# tle984x register map
Vendor: Infineon; File version: 1.9.5
CPU: CM0 r2p1, little endian, no MPU, no FPU, 2 interrupt priority bits
Registers are 32-bit, read-write, reset 0x0 unless marked. A register's access mark holds for its fields unless they carry their own. Offsets are from the block's base; [hi:lo] are bit positions; 'fields as' and 'values as' point back to an identical list.

## LS — Low-side switch registers
Base 0x4001C000
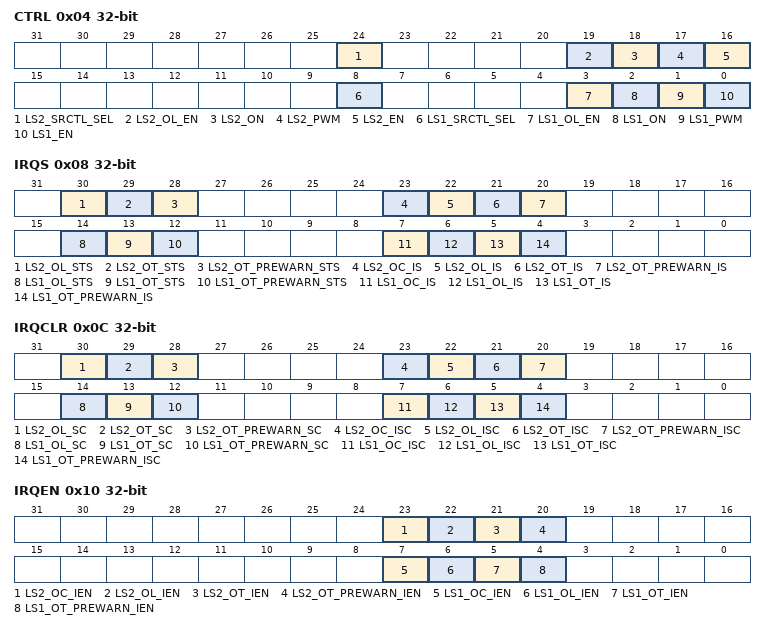
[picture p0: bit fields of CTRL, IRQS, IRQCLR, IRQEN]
0x04 CTRL — Low-side driver control register
  [24] LS2_SRCTL_SEL — Low-side switch 2 slew rate selection
    0=SLOW (Slow slew rate is selected); 1=FAST (Fast slew rate is selected)
  [19] LS2_OL_EN — Open load detection enable
    0=DISABLE (Open load detection); 1=ENABLE (Open load detection)
  [18] LS2_ON — Low-Side switch 2 on/off
    0=OFF (Switches LS2 off); 1=ON (Turns LS2 on)
  [17] LS2_PWM — Low-side switch 2 PWM enable
    0=DISABLE (Normal mode controlled by LS2_ON); 1=ENABLE (Enables LS2 for PWM mode)
  [16] LS2_EN — Low-side switch 2 enable
    0=DISABLE (Disables LS2); 1=ENABLE (Enables LS2)
  [8] LS1_SRCTL_SEL — Low-side switch 1 slew rate selection
    values as LS2_SRCTL_SEL
  [3] LS1_OL_EN — Open load detection enable
    values as LS2_OL_EN
  [2] LS1_ON — Low-side switch 1 on/off
    0=OFF (Switches LS1 off); 1=ON (Turns LS1 on)
  [1] LS1_PWM — Low-side switch 1 PWM enable
    0=DISABLE (Normal mode controlled by LS1_ON); 1=ENABLE (Enables LS1 for PWM mode)
  [0] LS1_EN — Low-side switch 1 enable
    0=DISABLE (Disables LS1); 1=ENABLE (Enables LS1)
0x08 IRQS — Low-side driver interrupt status register
  [30] LS2_OL_STS — Low-side 2 open load status
    0=NO_OPEN_LOAD (No open load condition occurred); 1=OPEN_LOAD (Open load occurred; switch is not automatically shut down. Write sets status)
  [29] LS2_OT_STS — Low-Side 2 overtemperature status
    0=NO_OVERTEMPERATURE (No overtemperature occurred); 1=OVERTEMPERATURE (Overtemperature occurred; switch is automatically shut down. Write sets status)
  [28] LS2_OT_PREWARN_STS — Low-Side 2 overtemperature prewarning status
    0=NO_OVERTEMPERATURE_PREWARN (No overtemperature prewarn occurred); 1=OVERTEMPERATURE_PREWARN (Overtemperature prewarn occurred. Write sets status)
  [23] LS2_OC_IS — Low-Side 2 overcurrent interrupt status
    0=NO_OVERCURRENT (No overcurrent condition occurred); 1=OVERCURRENT (Overcurrent occurred; switch is automatically shut down. Write sets status)
  [22] LS2_OL_IS — Low-Side 2 open load interrupt status
    values as LS2_OL_STS
  [21] LS2_OT_IS — Low-Side 2 overtemperature interrupt status
    values as LS2_OT_STS
  [20] LS2_OT_PREWARN_IS — Low-Side 2 overtemperature prewarning interrupt status
    values as LS2_OT_PREWARN_STS
  [14] LS1_OL_STS — Low-Side 1 open load status
    values as LS2_OL_STS
  [13] LS1_OT_STS — Low-Side 1 overtemperature status
    values as LS2_OT_STS
  [12] LS1_OT_PREWARN_STS — Low-Side 1 overtemperature prewarning status
    0=NO_OVERTEMPERATURE_PREWARN (No overtemperature prewarn occurred); 1=OVERTEMPERATURE (Overtemperature prewarn occurred; Write sets status)
  [7] LS1_OC_IS — Low-Side 1 overcurrent interrupt status
    values as LS2_OC_IS
  [6] LS1_OL_IS — Low-Side 1 open load interrupt status
    values as LS2_OL_STS
  [5] LS1_OT_IS — Low-Side 1 overtemperature interrupt status
    values as LS2_OT_STS
  [4] LS1_OT_PREWARN_IS — Low-Side 1 overtemperature prewarning interrupt status
    0=NO_OVERTEMPERATURE_PREWARN (No overtemperature prewarn occurred.); 1=OVERTEMPERATURE_PREWARN (Overtemperature prewarn occurred. Write sets status)
0x0C IRQCLR — Low-side driver interrupt status clear register
  [all] fields
    0=NO_CLEAR; 1=CLEAR
  [30] LS2_OL_SC wo — Low-side 2 open load status clear
  [29] LS2_OT_SC wo — Low-side switch 2 overtemperature status clear
  [28] LS2_OT_PREWARN_SC wo — Low-side 2 overtemperature prewarn status clear
  [23] LS2_OC_ISC wo — Low-side 2 overcurrent interrupt status clear
  [22] LS2_OL_ISC wo — Low-side 2 open load interrupt status clear
  [21] LS2_OT_ISC wo — Low-side 2 overtemperature interrupt status clear
  [20] LS2_OT_PREWARN_ISC wo — Low-side 2 overtemperature prewarn interrupt status clear
  [14] LS1_OL_SC wo — Low-side 1 open load status clear
  [13] LS1_OT_SC wo — Low-side 1 overtemperature status clear
  [12] LS1_OT_PREWARN_SC wo — Low-side 1 overtemperature prewarn status clear
  [7] LS1_OC_ISC wo — Low-side 1 overcurrent interrupt status clear
  [6] LS1_OL_ISC wo — Low-side 1 open load interrupt status clear
  [5] LS1_OT_ISC wo — Low-side 1 overtemperature interrupt status clear
  [4] LS1_OT_PREWARN_ISC wo — Low-side 1 overtemperature prewarn interrupt status clear
0x10 IRQEN — Low-side driver interrupt enable register
  [all] fields
    0=DISABLE (Disabled); 1=ENABLE (Enabled)
  [23] LS2_OC_IEN — Low-side 2 overcurrent interrupt enable
  [22] LS2_OL_IEN — Low-side 2 open load interrupt enable
  [21] LS2_OT_IEN — Low-side 2 overtemperature interrupt enable
  [20] LS2_OT_PREWARN_IEN — Low-side 2 overtemperature prewarn interrupt enable
  [7] LS1_OC_IEN — Low-side 1 overcurrent interrupt enable
  [6] LS1_OL_IEN — Low-side 1 open load interrupt enable
  [5] LS1_OT_IEN — Low-side 1 overtemperature interrupt enable
  [4] LS1_OT_PREWARN_IEN — Low-side 1 overtemperature prewarn interrupt enable
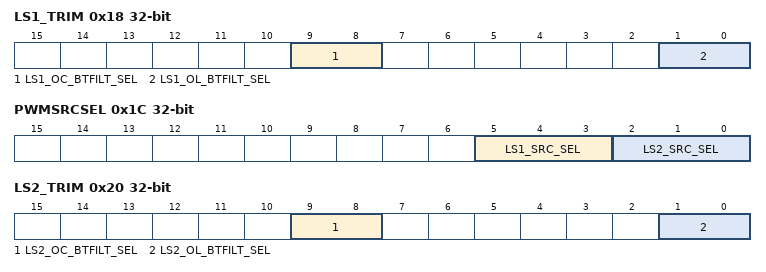
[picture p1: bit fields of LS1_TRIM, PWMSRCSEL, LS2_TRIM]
0x18 LS1_TRIM — Low-side 1 reference current trimming register
  [9:8] LS1_OC_BTFILT_SEL — Overcurrent blanktime select for LS1
    0=4 us filter time; 1=8 us filter time; 2=16 us filter time; 3=32 us filter time
  [1:0] LS1_OL_BTFILT_SEL — Open load blank time select for LS1
    values as LS1_OC_BTFILT_SEL
0x1C PWMSRCSEL — Low-side PWM source selection register
  [5:3] LS1_SRC_SEL — LS1 PWM source selection
    0=CC60 (PWM output of CCU6 (CC)); 1=CC61 (PWM output of CCU6 (CC)); 2=CC62 (PWM output of CCU6 (CC)); 3=COUT60 (PWM output of CCU6 (COUT)); 4=COUT61 (PWM output of CCU6 (COUT)); 5=COUT62 (PWM output of CCU6 (COUT)); 6=T3OUT (PWM output of GPT12)
  [2:0] LS2_SRC_SEL — LS2 PWM source selection
    values as LS1_SRC_SEL
0x20 LS2_TRIM — Low-side 2 reference current trimming register
  [9:8] LS2_OC_BTFILT_SEL — Overcurrent blank time select for LS2
    values as LS1_TRIM.LS1_OC_BTFILT_SEL
  [1:0] LS2_OL_BTFILT_SEL — Open load blank time select for LS2
    values as LS1_TRIM.LS1_OC_BTFILT_SEL
